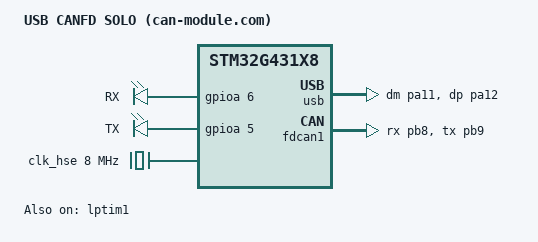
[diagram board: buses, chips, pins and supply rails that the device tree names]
/*
 * Copyright (c) 2026 Oleksii Mamontov <mamontov1@gmail.com>
 * SPDX-License-Identifier: Apache-2.0
 */

/dts-v1/;
#include <st/g4/stm32g431X8.dtsi>
#include <st/g4/stm32g431c(6-8-b)tx-pinctrl.dtsi>

/ {
	model = "USB CANFD SOLO (can-module.com)";
	compatible = "canmodule,usbcanfd-oleksii-g431";

	chosen {
		zephyr,sram = &sram0;
		zephyr,flash = &flash0;
		zephyr,canbus = &fdcan1;
	};

	aliases {
		led0 = &led_rx;
		led1 = &led_tx;
	};

	leds: leds {
		compatible = "gpio-leds";

		led_rx: led_rx {
			gpios = <&gpioa 6 GPIO_ACTIVE_HIGH>;
			label = "RX";
		};

		led_tx: led_tx {
			gpios = <&gpioa 5 GPIO_ACTIVE_HIGH>;
			label = "TX";
		};
	};
};

&clk_hse {
	clock-frequency = <DT_FREQ_M(8)>; /* HSE 8 Mhz */
	status = "okay";
};

&clk_hsi48 {
	status = "okay";
};

&pll {
	div-m = <2>;
	mul-n = <80>;
	div-p = <2>;
	div-q = <4>;
	div-r = <2>;
	clocks = <&clk_hse>;
	status = "okay";
};

&rcc {
	clocks = <&pll>;
	clock-frequency = <DT_FREQ_M(160)>;
	ahb-prescaler = <1>;
	apb1-prescaler = <1>;
	apb2-prescaler = <1>;
};

stm32_lp_tick_source: &lptim1 {
	clocks = <&rcc STM32_CLOCK(APB1, 31)>,
		 <&rcc STM32_SRC_LSE LPTIM1_SEL(3)>;
	status = "okay";
};

zephyr_udc0: &usb {
	pinctrl-0 = <&usb_dm_pa11 &usb_dp_pa12>;
	pinctrl-names = "default";
	clocks = <&rcc STM32_CLOCK(APB1, 23)>,
		 <&rcc STM32_SRC_HSI48 CLK48_SEL(0)>;
	status = "okay";
};

&fdcan1 {
	pinctrl-0 = <&fdcan1_rx_pb8 &fdcan1_tx_pb9>;
	pinctrl-names = "default";
	clocks = <&rcc STM32_CLOCK(APB1, 25)>,
		 <&rcc STM32_SRC_PLL_Q FDCAN_SEL(1)>;
	status = "okay";
};
